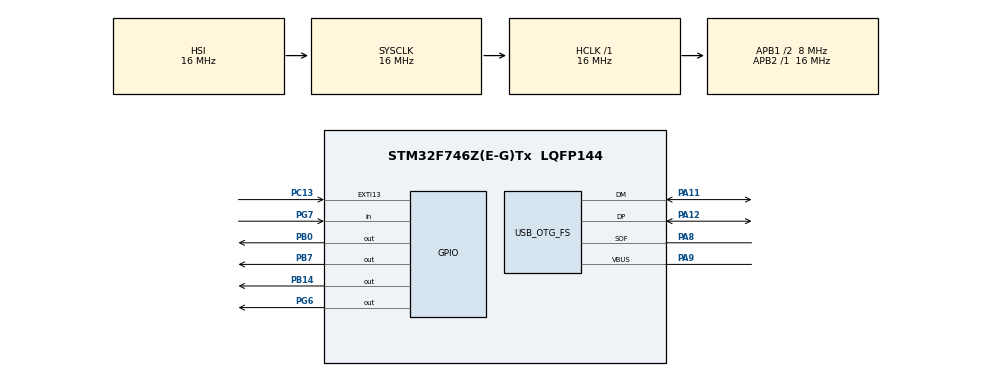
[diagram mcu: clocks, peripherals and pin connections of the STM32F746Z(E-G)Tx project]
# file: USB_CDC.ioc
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Mcu.Family=STM32F7
Mcu.Name=STM32F746Z(E-G)Tx
Mcu.Package=LQFP144
NVIC.OTG_FS_IRQn=true\:0\:0\:false\:false\:true
NVIC.PriorityGroup=NVIC_PRIORITYGROUP_4
PA1.GPIO_Mode=GPIO_MODE_AF_PP
PA1.GPIO_PuPd=GPIO_NOPULL
PA1.GPIO_Speed=GPIO_SPEED_FREQ_VERY_HIGH
PA1.Signal=ETH_REF_CLK
PA10.Signal=USB_OTG_FS_ID
PA11.GPIO_Mode=GPIO_MODE_AF_PP
PA11.GPIO_PuPd=GPIO_NOPULL
PA11.GPIO_Speed=GPIO_SPEED_FREQ_VERY_HIGH
PA11.Mode=Host_Only
PA11.Signal=USB_OTG_FS_DM
PA12.GPIO_Mode=GPIO_MODE_AF_PP
PA12.GPIO_PuPd=GPIO_NOPULL
PA12.GPIO_Speed=GPIO_SPEED_FREQ_VERY_HIGH
PA12.Mode=Host_Only
PA12.Signal=USB_OTG_FS_DP
PA13.Signal=SYS_JTMS-SWDIO
PA14.Signal=SYS_JTCK-SWCLK
PA2.GPIO_Mode=GPIO_MODE_AF_PP
PA2.GPIO_PuPd=GPIO_NOPULL
PA2.GPIO_Speed=GPIO_SPEED_FREQ_VERY_HIGH
PA2.Signal=ETH_MDIO
PA7.GPIO_Mode=GPIO_MODE_AF_PP
PA7.GPIO_PuPd=GPIO_NOPULL
PA7.GPIO_Speed=GPIO_SPEED_FREQ_VERY_HIGH
PA7.Signal=ETH_CRS_DV
PA8.GPIO_Mode=GPIO_MODE_AF_PP
PA8.GPIO_PuPd=GPIO_NOPULL
PA8.GPIO_Speed=GPIO_SPEED_FREQ_VERY_HIGH
PA8.Mode=Activate_SOF_FS
PA8.Signal=USB_OTG_FS_SOF
PA9.GPIO_Mode=GPIO_MODE_INPUT
PA9.GPIO_PuPd=GPIO_NOPULL
PA9.Mode=Activate_VBUS
PA9.Signal=USB_OTG_FS_VBUS
PB0.GPIO_ModeDefaultOutputPP=GPIO_MODE_OUTPUT_PP
PB0.GPIO_PuPd=GPIO_NOPULL
PB0.GPIO_Speed=GPIO_SPEED_FREQ_LOW
PB0.PinState=GPIO_PIN_RESET
PB0.Signal=GPIO_Output
PB13.GPIO_Mode=GPIO_MODE_AF_PP
PB13.GPIO_PuPd=GPIO_NOPULL
PB13.GPIO_Speed=GPIO_SPEED_FREQ_VERY_HIGH
PB13.Signal=ETH_TXD1
PB14.GPIO_ModeDefaultOutputPP=GPIO_MODE_OUTPUT_PP
PB14.GPIO_PuPd=GPIO_NOPULL
PB14.GPIO_Speed=GPIO_SPEED_FREQ_LOW
PB14.PinState=GPIO_PIN_RESET
PB14.Signal=GPIO_Output
PB3.Signal=SYS_JTDO-SWO
PB7.GPIO_ModeDefaultOutputPP=GPIO_MODE_OUTPUT_PP
PB7.GPIO_PuPd=GPIO_NOPULL
PB7.GPIO_Speed=GPIO_SPEED_FREQ_LOW
PB7.PinState=GPIO_PIN_RESET
PB7.Signal=GPIO_Output
PC1.GPIO_Mode=GPIO_MODE_AF_PP
PC1.GPIO_PuPd=GPIO_NOPULL
PC1.GPIO_Speed=GPIO_SPEED_FREQ_VERY_HIGH
PC1.Signal=ETH_MDC
PC13.GPIO_ModeDefaultEXTI=GPIO_MODE_IT_RISING
PC13.GPIO_PuPd=GPIO_NOPULL
PC13.Signal=GPXTI13
PC14/OSC32_IN.Signal=RCC_OSC32_IN
PC15/OSC32_OUT.Signal=RCC_OSC32_OUT
PC4.GPIO_Mode=GPIO_MODE_AF_PP
PC4.GPIO_PuPd=GPIO_NOPULL
PC4.GPIO_Speed=GPIO_SPEED_FREQ_VERY_HIGH
PC4.Signal=ETH_RXD0
PC5.GPIO_Mode=GPIO_MODE_AF_PP
PC5.GPIO_PuPd=GPIO_NOPULL
PC5.GPIO_Speed=GPIO_SPEED_FREQ_VERY_HIGH
PC5.Signal=ETH_RXD1
PD8.GPIO_Mode=GPIO_MODE_AF_PP
PD8.GPIO_PuPd=GPIO_NOPULL
PD8.GPIO_Speed=GPIO_SPEED_FREQ_VERY_HIGH
PD8.Signal=USART3_TX
PD9.GPIO_Mode=GPIO_MODE_AF_PP
PD9.GPIO_PuPd=GPIO_NOPULL
PD9.GPIO_Speed=GPIO_SPEED_FREQ_VERY_HIGH
PD9.Signal=USART3_RX
PG11.GPIO_Mode=GPIO_MODE_AF_PP
PG11.GPIO_PuPd=GPIO_NOPULL
PG11.GPIO_Speed=GPIO_SPEED_FREQ_VERY_HIGH
PG11.Signal=ETH_TX_EN
PG13.GPIO_Mode=GPIO_MODE_AF_PP
PG13.GPIO_PuPd=GPIO_NOPULL
PG13.GPIO_Speed=GPIO_SPEED_FREQ_VERY_HIGH
PG13.Signal=ETH_TXD0
PG6.GPIO_ModeDefaultOutputPP=GPIO_MODE_OUTPUT_PP
PG6.GPIO_PuPd=GPIO_NOPULL
PG6.GPIO_Speed=GPIO_SPEED_FREQ_LOW
PG6.PinState=GPIO_PIN_RESET
PG6.Signal=GPIO_Output
PG7.GPIO_Mode=GPIO_MODE_INPUT
PG7.GPIO_PuPd=GPIO_NOPULL
PG7.Signal=GPIO_Input
PH0/OSC_IN.Signal=RCC_OSC_IN
PH1/OSC_OUT.Signal=RCC_OSC_OUT
ProjectManager.HeapSize=0x200
ProjectManager.StackSize=0x400
ProjectManager.TargetToolchain=SW4STM32
RCC.48MHZClocksFreq_Value=24000000
RCC.AHBFreq_Value=16000000
RCC.APB1CLKDivider=RCC_HCLK_DIV2
RCC.APB1Freq_Value=8000000
RCC.APB1TimFreq_Value=16000000
RCC.APB2Freq_Value=16000000
RCC.APB2TimFreq_Value=16000000
RCC.CortexFreq_Value=16000000
RCC.HCLKFreq_Value=16000000
RCC.HSE_VALUE=8000000
RCC.HSI_VALUE=16000000
RCC.LSE_VALUE=32768
RCC.PLL48CLockSelection=RCC_CLK48SOURCE_PLLSAIP
RCC.PLLMUL=RCC_PLL_MUL9
RCC.PLLQ=3
RCC.PLLSource=RCC_PLLSOURCE_HSI
RCC.PRESCALERUSB=RCC_USBCLKSOURCE_PLL_DIV1_5
RCC.SYSCLKFreq_VALUE=16000000
RCC.SYSCLKSourceVirtual=RCC_SYSCLKSOURCE_PLLCLK
RCC.USBFreq_Value=96000000
RCC.VCOOutputFreq_Value=192000000
USB_HOST.USBH_HandleTypeDef-CDC_FS=hUsbHostFS
USB_HOST.VirtualModeFS=Cdc
USB_OTG_FS.VirtualMode=Host_Only
USB_OTG_FS.phy_itface=HCD_PHY_EMBEDDED
VP_USB_HOST_VS_USB_HOST_CDC_FS.Mode=CDC_FS
board=NUCLEO-F746ZG

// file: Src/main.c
/**
  ******************************************************************************
  * File Name          : main.c
  * Description        : Main program body
  ******************************************************************************
  *
  * Copyright (c) 2017 STMicroelectronics International N.V.
  * All rights reserved.
  *
  * Redistribution and use in source and binary forms, with or without
  * modification, are permitted, provided that the following conditions are met:
  *
  * 1. Redistribution of source code must retain the above copyright notice,
  *    this list of conditions and the following disclaimer.
  * 2. Redistributions in binary form must reproduce the above copyright notice,
  *    this list of conditions and the following disclaimer in the documentation
  *    and/or other materials provided with the distribution.
  * 3. Neither the name of STMicroelectronics nor the names of other
  *    contributors to this software may be used to endorse or promote products
  *    derived from this software without specific written permission.
  * 4. This software, including modifications and/or derivative works of this
  *    software, must execute solely and exclusively on microcontroller or
  *    microprocessor devices manufactured by or for STMicroelectronics.
  * 5. Redistribution and use of this software other than as permitted under
  *    this license is void and will automatically terminate your rights under
  *    this license.
  *
  * THIS SOFTWARE IS PROVIDED BY STMICROELECTRONICS AND CONTRIBUTORS "AS IS"
  * AND ANY EXPRESS, IMPLIED OR STATUTORY WARRANTIES, INCLUDING, BUT NOT
  * LIMITED TO, THE IMPLIED WARRANTIES OF MERCHANTABILITY, FITNESS FOR A
  * PARTICULAR PURPOSE AND NON-INFRINGEMENT OF THIRD PARTY INTELLECTUAL PROPERTY
  * RIGHTS ARE DISCLAIMED TO THE FULLEST EXTENT PERMITTED BY LAW. IN NO EVENT
  * SHALL STMICROELECTRONICS OR CONTRIBUTORS BE LIABLE FOR ANY DIRECT, INDIRECT,
  * INCIDENTAL, SPECIAL, EXEMPLARY, OR CONSEQUENTIAL DAMAGES (INCLUDING, BUT NOT
  * LIMITED TO, PROCUREMENT OF SUBSTITUTE GOODS OR SERVICES; LOSS OF USE, DATA,
  * OR PROFITS; OR BUSINESS INTERRUPTION) HOWEVER CAUSED AND ON ANY THEORY OF
  * LIABILITY, WHETHER IN CONTRACT, STRICT LIABILITY, OR TORT (INCLUDING
  * NEGLIGENCE OR OTHERWISE) ARISING IN ANY WAY OUT OF THE USE OF THIS SOFTWARE,
  * EVEN IF ADVISED OF THE POSSIBILITY OF SUCH DAMAGE.
  *
  ******************************************************************************
  */
#include "main.h"
#include "stm32f7xx_hal.h"
#include "usb_host.h"

/* USER CODE BEGIN PV */
/* Private variables ---------------------------------------------------------*/

/* USER CODE END PV */

void SystemClock_Config(void);
void Error_Handler(void);
static void MX_GPIO_Init(void);
void MX_USB_HOST_Process(void);

/* USER CODE BEGIN PFP */
/* Private function prototypes -----------------------------------------------*/

/* USER CODE END PFP */

int main(void)
{

  /* MCU Configuration----------------------------------------------------------*/

  /* Reset of all peripherals, Initializes the Flash interface and the Systick. */
  HAL_Init();

  /* Configure the system clock */
  SystemClock_Config();

  /* Initialize all configured peripherals */
  MX_GPIO_Init();
  MX_USB_HOST_Init();

  /* Infinite loop */
  while (1)
  {
    MX_USB_HOST_Process();

  /* USER CODE BEGIN 3 */
    process();

  }
  /* USER CODE END 3 */

}

/** System Clock Configuration
*/
void SystemClock_Config(void)
{

  RCC_OscInitTypeDef RCC_OscInitStruct;
  RCC_ClkInitTypeDef RCC_ClkInitStruct;
  RCC_PeriphCLKInitTypeDef PeriphClkInitStruct;

    /**Macro to configure the PLL multiplication factor
    */
  __HAL_RCC_PLL_PLLM_CONFIG(16);

    /**Macro to configure the PLL clock source
    */
  __HAL_RCC_PLL_PLLSOURCE_CONFIG(RCC_PLLSOURCE_HSI);

    /**Configure the main internal regulator output voltage
    */
  __HAL_RCC_PWR_CLK_ENABLE();

  __HAL_PWR_VOLTAGESCALING_CONFIG(PWR_REGULATOR_VOLTAGE_SCALE3);

    /**Initializes the CPU, AHB and APB busses clocks
    */
  RCC_OscInitStruct.OscillatorType = RCC_OSCILLATORTYPE_HSI;
  RCC_OscInitStruct.HSIState = RCC_HSI_ON;
  RCC_OscInitStruct.HSICalibrationValue = 16;
  RCC_OscInitStruct.PLL.PLLState = RCC_PLL_NONE;
  RCC_OscInitStruct.PLL.PLLSource = RCC_PLLSOURCE_HSI;
  RCC_OscInitStruct.PLL.PLLM = 16;
  if (HAL_RCC_OscConfig(&RCC_OscInitStruct) != HAL_OK)
  {
    Error_Handler();
  }

    /**Initializes the CPU, AHB and APB busses clocks
    */
  RCC_ClkInitStruct.ClockType = RCC_CLOCKTYPE_HCLK|RCC_CLOCKTYPE_SYSCLK
                              |RCC_CLOCKTYPE_PCLK1|RCC_CLOCKTYPE_PCLK2;
  RCC_ClkInitStruct.SYSCLKSource = RCC_SYSCLKSOURCE_HSI;
  RCC_ClkInitStruct.AHBCLKDivider = RCC_SYSCLK_DIV1;
  RCC_ClkInitStruct.APB1CLKDivider = RCC_HCLK_DIV2;
  RCC_ClkInitStruct.APB2CLKDivider = RCC_HCLK_DIV1;

  if (HAL_RCC_ClockConfig(&RCC_ClkInitStruct, FLASH_LATENCY_0) != HAL_OK)
  {
    Error_Handler();
  }

  PeriphClkInitStruct.PeriphClockSelection = RCC_PERIPHCLK_CLK48;
  PeriphClkInitStruct.PLLSAI.PLLSAIN = 192;
  PeriphClkInitStruct.PLLSAI.PLLSAIR = 2;
  PeriphClkInitStruct.PLLSAI.PLLSAIQ = 2;
  PeriphClkInitStruct.PLLSAI.PLLSAIP = RCC_PLLSAIP_DIV2;
  PeriphClkInitStruct.PLLSAIDivQ = 1;
  PeriphClkInitStruct.PLLSAIDivR = RCC_PLLSAIDIVR_2;
  PeriphClkInitStruct.Clk48ClockSelection = RCC_CLK48SOURCE_PLLSAIP;
  if (HAL_RCCEx_PeriphCLKConfig(&PeriphClkInitStruct) != HAL_OK)
  {
    Error_Handler();
  }

    /**Configure the Systick interrupt time
    */
  HAL_SYSTICK_Config(HAL_RCC_GetHCLKFreq()/1000);

    /**Configure the Systick
    */
  HAL_SYSTICK_CLKSourceConfig(SYSTICK_CLKSOURCE_HCLK);

  /* SysTick_IRQn interrupt configuration */
  HAL_NVIC_SetPriority(SysTick_IRQn, 0, 0);
}

/** Configure pins as
        * Analog
        * Input
        * Output
        * EVENT_OUT
        * EXTI
     PC1   ------> ETH_MDC
     PA1   ------> ETH_REF_CLK
     PA2   ------> ETH_MDIO
     PA7   ------> ETH_CRS_DV
     PC4   ------> ETH_RXD0
     PC5   ------> ETH_RXD1
     PB13   ------> ETH_TXD1
     PD8   ------> USART3_TX
     PD9   ------> USART3_RX
     PG11   ------> ETH_TX_EN
     PG13   ------> ETH_TXD0
*/
static void MX_GPIO_Init(void)
{

  GPIO_InitTypeDef GPIO_InitStruct;

  /* GPIO Ports Clock Enable */
  __HAL_RCC_GPIOC_CLK_ENABLE();
  __HAL_RCC_GPIOH_CLK_ENABLE();
  __HAL_RCC_GPIOA_CLK_ENABLE();
  __HAL_RCC_GPIOB_CLK_ENABLE();
  __HAL_RCC_GPIOD_CLK_ENABLE();
  __HAL_RCC_GPIOG_CLK_ENABLE();

  /*Configure GPIO pin Output Level */
  HAL_GPIO_WritePin(GPIOB, GPIO_PIN_0|GPIO_PIN_14|GPIO_PIN_7, GPIO_PIN_RESET);

  /*Configure GPIO pin Output Level */
  HAL_GPIO_WritePin(GPIOG, GPIO_PIN_6, GPIO_PIN_RESET);

  /*Configure GPIO pin : PC13 */
  GPIO_InitStruct.Pin = GPIO_PIN_13;
  GPIO_InitStruct.Mode = GPIO_MODE_IT_RISING;
  GPIO_InitStruct.Pull = GPIO_NOPULL;
  HAL_GPIO_Init(GPIOC, &GPIO_InitStruct);

  /*Configure GPIO pins : PC1 PC4 PC5 */
  GPIO_InitStruct.Pin = GPIO_PIN_1|GPIO_PIN_4|GPIO_PIN_5;
  GPIO_InitStruct.Mode = GPIO_MODE_AF_PP;
  GPIO_InitStruct.Pull = GPIO_NOPULL;
  GPIO_InitStruct.Speed = GPIO_SPEED_FREQ_VERY_HIGH;
  GPIO_InitStruct.Alternate = GPIO_AF11_ETH;
  HAL_GPIO_Init(GPIOC, &GPIO_InitStruct);

  /*Configure GPIO pins : PA1 PA2 PA7 */
  GPIO_InitStruct.Pin = GPIO_PIN_1|GPIO_PIN_2|GPIO_PIN_7;
  GPIO_InitStruct.Mode = GPIO_MODE_AF_PP;
  GPIO_InitStruct.Pull = GPIO_NOPULL;
  GPIO_InitStruct.Speed = GPIO_SPEED_FREQ_VERY_HIGH;
  GPIO_InitStruct.Alternate = GPIO_AF11_ETH;
  HAL_GPIO_Init(GPIOA, &GPIO_InitStruct);

  /*Configure GPIO pins : PB0 PB14 PB7 */
  GPIO_InitStruct.Pin = GPIO_PIN_0|GPIO_PIN_14|GPIO_PIN_7;
  GPIO_InitStruct.Mode = GPIO_MODE_OUTPUT_PP;
  GPIO_InitStruct.Pull = GPIO_NOPULL;
  GPIO_InitStruct.Speed = GPIO_SPEED_FREQ_LOW;
  HAL_GPIO_Init(GPIOB, &GPIO_InitStruct);

  /*Configure GPIO pin : PB13 */
  GPIO_InitStruct.Pin = GPIO_PIN_13;
  GPIO_InitStruct.Mode = GPIO_MODE_AF_PP;
  GPIO_InitStruct.Pull = GPIO_NOPULL;
  GPIO_InitStruct.Speed = GPIO_SPEED_FREQ_VERY_HIGH;
  GPIO_InitStruct.Alternate = GPIO_AF11_ETH;
  HAL_GPIO_Init(GPIOB, &GPIO_InitStruct);

  /*Configure GPIO pins : PD8 PD9 */
  GPIO_InitStruct.Pin = GPIO_PIN_8|GPIO_PIN_9;
  GPIO_InitStruct.Mode = GPIO_MODE_AF_PP;
  GPIO_InitStruct.Pull = GPIO_NOPULL;
  GPIO_InitStruct.Speed = GPIO_SPEED_FREQ_VERY_HIGH;
  GPIO_InitStruct.Alternate = GPIO_AF7_USART3;
  HAL_GPIO_Init(GPIOD, &GPIO_InitStruct);

  /*Configure GPIO pin : PG6 */
  GPIO_InitStruct.Pin = GPIO_PIN_6;
  GPIO_InitStruct.Mode = GPIO_MODE_OUTPUT_PP;
  GPIO_InitStruct.Pull = GPIO_NOPULL;
  GPIO_InitStruct.Speed = GPIO_SPEED_FREQ_LOW;
  HAL_GPIO_Init(GPIOG, &GPIO_InitStruct);

  /*Configure GPIO pin : PG7 */
  GPIO_InitStruct.Pin = GPIO_PIN_7;
  GPIO_InitStruct.Mode = GPIO_MODE_INPUT;
  GPIO_InitStruct.Pull = GPIO_NOPULL;
  HAL_GPIO_Init(GPIOG, &GPIO_InitStruct);

  /*Configure GPIO pins : PG11 PG13 */
  GPIO_InitStruct.Pin = GPIO_PIN_11|GPIO_PIN_13;
  GPIO_InitStruct.Mode = GPIO_MODE_AF_PP;
  GPIO_InitStruct.Pull = GPIO_NOPULL;
  GPIO_InitStruct.Speed = GPIO_SPEED_FREQ_VERY_HIGH;
  GPIO_InitStruct.Alternate = GPIO_AF11_ETH;
  HAL_GPIO_Init(GPIOG, &GPIO_InitStruct);

}

void Error_Handler(void)
{
  while(1)
  {
  }
}

/************************ (C) COPYRIGHT STMicroelectronics *****END OF FILE****/
